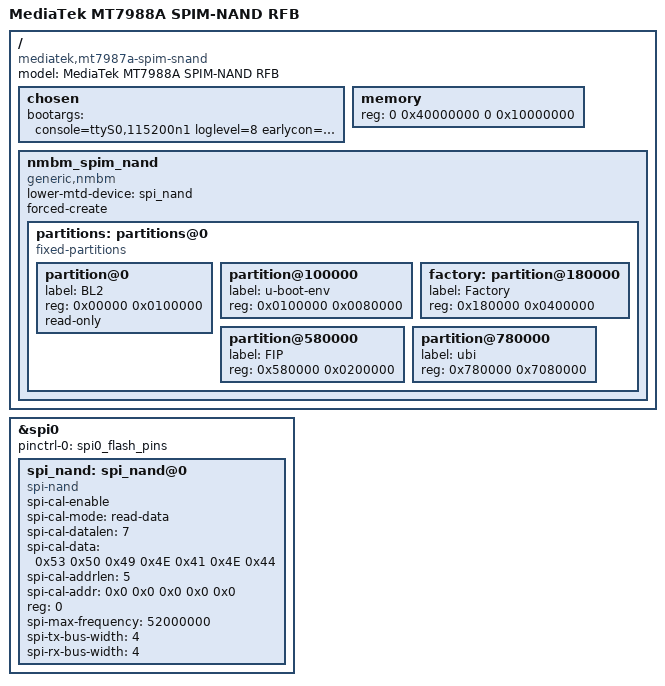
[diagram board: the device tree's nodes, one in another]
// SPDX-License-Identifier: (GPL-2.0 OR MIT)
/*
 * Copyright (C) 2023 MediaTek Inc.
 * Author: Sam.Shih <sam.shih@mediatek.com>
 */

/dts-v1/;
#include "mt7987a.dtsi"

/ {
	model = "MediaTek MT7988A SPIM-NAND RFB";
	compatible = "mediatek,mt7987a-spim-snand",
		     "mediatek,mt7987a", "mediatek,mt7987";

	chosen {
		bootargs = "console=ttyS0,115200n1 loglevel=8  \
			    earlycon=uart8250,mmio32,0x11000000 \
			    pci=pcie_bus_perf";
	};

	memory {
		reg = <0 0x40000000 0 0x10000000>;
	};

	nmbm_spim_nand {
		compatible = "generic,nmbm";

		#address-cells = <1>;
		#size-cells = <1>;

		lower-mtd-device = <&spi_nand>;
		forced-create;

		partitions: partitions@0 {
			compatible = "fixed-partitions";
			#address-cells = <1>;
			#size-cells = <1>;
		};
	};
};

&partitions {
	partition@0 {
		label = "BL2";
		reg = <0x00000 0x0100000>;
		read-only;
	};
	partition@100000 {
		label = "u-boot-env";
		reg = <0x0100000 0x0080000>;
	};
	factory: partition@180000 {
		label = "Factory";
		reg = <0x180000 0x0400000>;
	};
	partition@580000 {
		label = "FIP";
		reg = <0x580000 0x0200000>;
	};
	partition@780000 {
		label = "ubi";
		reg = <0x780000 0x7080000>;
	};
};

&spi0 {
	pinctrl-names = "default";
	pinctrl-0 = <&spi0_flash_pins>;
	status = "okay";

	spi_nand: spi_nand@0 {
		#address-cells = <1>;
		#size-cells = <1>;
		compatible = "spi-nand";
		spi-cal-enable;
		spi-cal-mode = "read-data";
		spi-cal-datalen = <7>;
		spi-cal-data = /bits/ 8 <0x53 0x50 0x49 0x4E 0x41 0x4E 0x44>;
		spi-cal-addrlen = <5>;
		spi-cal-addr = /bits/ 32 <0x0 0x0 0x0 0x0 0x0>;
		reg = <0>;
		spi-max-frequency = <52000000>;
		spi-tx-bus-width = <4>;
		spi-rx-bus-width = <4>;
	};
};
